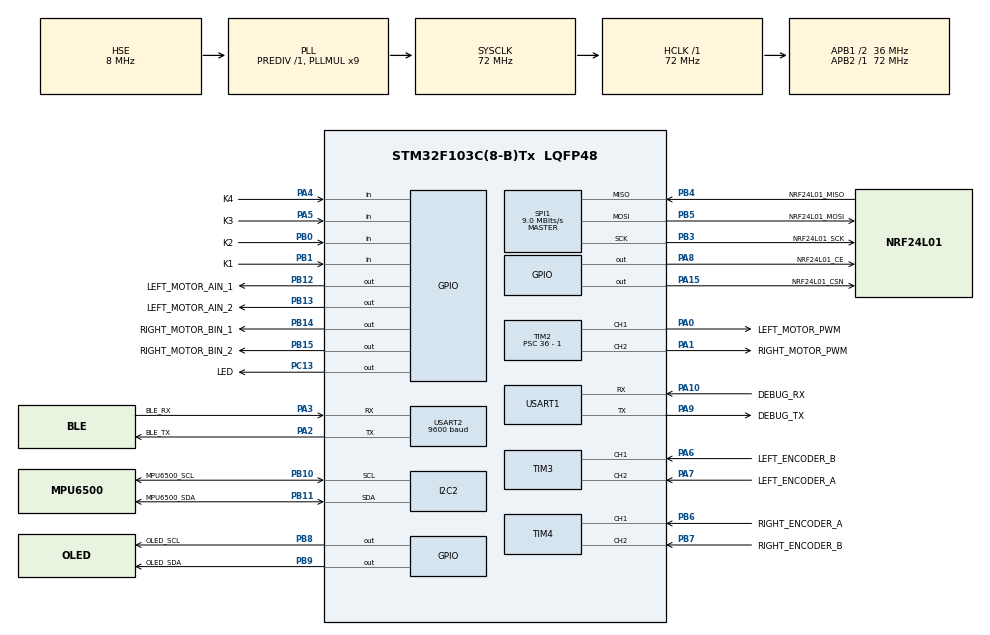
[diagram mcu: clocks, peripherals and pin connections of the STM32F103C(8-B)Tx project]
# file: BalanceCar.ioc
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FREERTOS.Tasks01=defaultTask,24,128,StartDefaultTask,Default,NULL,Dynamic,NULL,NULL
FREERTOS.configTOTAL_HEAP_SIZE=6144
Mcu.Family=STM32F1
Mcu.Name=STM32F103C(8-B)Tx
Mcu.Package=LQFP48
NVIC.PriorityGroup=NVIC_PRIORITYGROUP_4
NVIC.TIM1_UP_IRQn=true\:15\:0\:false\:false\:true\:false\:false\:true\:true
NVIC.TimeBase=TIM1_UP_IRQn
NVIC.TimeBaseIP=TIM1
NVIC.USART1_IRQn=true\:10\:0\:true\:false\:true\:true\:true\:true\:true
NVIC.USART2_IRQn=true\:7\:0\:true\:false\:true\:true\:true\:true\:true
PA0-WKUP.GPIO_Label=LEFT_MOTOR_PWM
PA0-WKUP.Signal=S_TIM2_CH1_ETR
PA1.GPIO_Label=RIGHT_MOTOR_PWM
PA1.Signal=S_TIM2_CH2
PA10.GPIO_Label=DEBUG_RX
PA10.Mode=Asynchronous
PA10.Signal=USART1_RX
PA13.Mode=Serial_Wire
PA13.Signal=SYS_JTMS-SWDIO
PA14.Mode=Serial_Wire
PA14.Signal=SYS_JTCK-SWCLK
PA15.GPIO_Label=NRF24L01_CSN
PA15.PinState=GPIO_PIN_SET
PA15.Signal=GPIO_Output
PA2.GPIO_Label=BLE_TX
PA2.Mode=Asynchronous
PA2.Signal=USART2_TX
PA3.GPIO_Label=BLE_RX
PA3.Mode=Asynchronous
PA3.Signal=USART2_RX
PA4.GPIO_Label=K4
PA4.GPIO_PuPd=GPIO_PULLUP
PA4.Signal=GPIO_Input
PA5.GPIO_Label=K3
PA5.GPIO_PuPd=GPIO_PULLUP
PA5.Signal=GPIO_Input
PA6.GPIO_Label=LEFT_ENCODER_B
PA6.Signal=S_TIM3_CH1
PA7.GPIO_Label=LEFT_ENCODER_A
PA7.Signal=S_TIM3_CH2
PA8.GPIO_Label=NRF24L01_CE
PA8.Signal=GPIO_Output
PA9.GPIO_Label=DEBUG_TX
PA9.Mode=Asynchronous
PA9.Signal=USART1_TX
PB0.GPIO_Label=K2
PB0.GPIO_PuPd=GPIO_PULLUP
PB0.Signal=GPIO_Input
PB1.GPIO_Label=K1
PB1.GPIO_PuPd=GPIO_PULLUP
PB1.Signal=GPIO_Input
PB10.GPIO_Label=MPU6500_SCL
PB10.Mode=I2C
PB10.Signal=I2C2_SCL
PB11.GPIO_Label=MPU6500_SDA
PB11.Mode=I2C
PB11.Signal=I2C2_SDA
PB12.GPIO_Label=LEFT_MOTOR_AIN_1
PB12.Signal=GPIO_Output
PB13.GPIO_Label=LEFT_MOTOR_AIN_2
PB13.Signal=GPIO_Output
PB14.GPIO_Label=RIGHT_MOTOR_BIN_1
PB14.Signal=GPIO_Output
PB15.GPIO_Label=RIGHT_MOTOR_BIN_2
PB15.Signal=GPIO_Output
PB3.GPIO_Label=NRF24L01_SCK
PB3.Mode=Full_Duplex_Master
PB3.Signal=SPI1_SCK
PB4.GPIO_Label=NRF24L01_MISO
PB4.GPIO_PuPd=GPIO_PULLUP
PB4.Mode=Full_Duplex_Master
PB4.Signal=SPI1_MISO
PB5.GPIO_Label=NRF24L01_MOSI
PB5.Mode=Full_Duplex_Master
PB5.Signal=SPI1_MOSI
PB6.GPIO_Label=RIGHT_ENCODER_A
PB6.Signal=S_TIM4_CH1
PB7.GPIO_Label=RIGHT_ENCODER_B
PB7.Signal=S_TIM4_CH2
PB8.GPIO_Label=OLED_SCL
PB8.GPIO_ModeDefaultOutputPP=GPIO_MODE_OUTPUT_OD
PB8.GPIO_PuPd=GPIO_NOPULL
PB8.PinState=GPIO_PIN_SET
PB8.Signal=GPIO_Output
PB9.GPIO_Label=OLED_SDA
PB9.GPIO_ModeDefaultOutputPP=GPIO_MODE_OUTPUT_OD
PB9.GPIO_PuPd=GPIO_NOPULL
PB9.PinState=GPIO_PIN_SET
PB9.Signal=GPIO_Output
PC13-TAMPER-RTC.GPIO_Label=LED
PC13-TAMPER-RTC.PinState=GPIO_PIN_SET
PC13-TAMPER-RTC.Signal=GPIO_Output
PC14-OSC32_IN.Mode=LSE-External-Oscillator
PC14-OSC32_IN.Signal=RCC_OSC32_IN
PC15-OSC32_OUT.Mode=LSE-External-Oscillator
PC15-OSC32_OUT.Signal=RCC_OSC32_OUT
PD0-OSC_IN.Mode=HSE-External-Oscillator
PD0-OSC_IN.Signal=RCC_OSC_IN
PD1-OSC_OUT.Mode=HSE-External-Oscillator
PD1-OSC_OUT.Signal=RCC_OSC_OUT
ProjectManager.HeapSize=0x200
ProjectManager.StackSize=0x400
ProjectManager.TargetToolchain=MDK-ARM V5.32
RCC.AHBFreq_Value=72000000
RCC.APB1CLKDivider=RCC_HCLK_DIV2
RCC.APB1Freq_Value=36000000
RCC.APB1TimFreq_Value=72000000
RCC.APB2Freq_Value=72000000
RCC.APB2TimFreq_Value=72000000
RCC.HCLKFreq_Value=72000000
RCC.PLLMUL=RCC_PLL_MUL9
RCC.PLLSourceVirtual=RCC_PLLSOURCE_HSE
RCC.SYSCLKFreq_VALUE=72000000
RCC.SYSCLKSource=RCC_SYSCLKSOURCE_PLLCLK
RCC.USBFreq_Value=72000000
SH.S_TIM2_CH1_ETR.0=TIM2_CH1,PWM Generation1 CH1
SH.S_TIM2_CH2.0=TIM2_CH2,PWM Generation2 CH2
SH.S_TIM3_CH1.0=TIM3_CH1,Encoder_Interface
SH.S_TIM3_CH2.0=TIM3_CH2,Encoder_Interface
SH.S_TIM4_CH1.0=TIM4_CH1,Encoder_Interface
SH.S_TIM4_CH2.0=TIM4_CH2,Encoder_Interface
SPI1.BaudRatePrescaler=SPI_BAUDRATEPRESCALER_8
SPI1.CalculateBaudRate=9.0 MBits/s
SPI1.Direction=SPI_DIRECTION_2LINES
SPI1.Mode=SPI_MODE_MASTER
SPI1.VirtualType=VM_MASTER
TIM2.Channel-PWM\ Generation1\ CH1=TIM_CHANNEL_1
TIM2.Channel-PWM\ Generation2\ CH2=TIM_CHANNEL_2
TIM2.Period=100 - 1
TIM2.Prescaler=36 - 1
TIM3.EncoderMode=TIM_ENCODERMODE_TI12
TIM3.IC1Filter=15
TIM3.IC2Filter=15
TIM4.EncoderMode=TIM_ENCODERMODE_TI12
TIM4.IC1Filter=15
TIM4.IC2Filter=15
USART1.VirtualMode=VM_ASYNC
USART2.BaudRate=9600
USART2.VirtualMode=VM_ASYNC
VP_FREERTOS_VS_CMSIS_V2.Mode=CMSIS_V2
VP_SYS_VS_tim1.Mode=TIM1
VP_TIM2_VS_ClockSourceINT.Mode=Internal
board=custom

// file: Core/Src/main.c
/* USER CODE BEGIN Header */
/**
  ******************************************************************************
  * @file           : main.c
  * @brief          : Main program body
  ******************************************************************************
  * @attention
  *
  * Copyright (c) 2026 STMicroelectronics.
  * All rights reserved.
  *
  * This software is licensed under terms that can be found in the LICENSE file
  * in the root directory of this software component.
  * If no LICENSE file comes with this software, it is provided AS-IS.
  *
  ******************************************************************************
  */
/* USER CODE END Header */
#include "main.h"
#include "cmsis_os.h"
#include "i2c.h"
#include "spi.h"
#include "tim.h"
#include "usart.h"
#include "gpio.h"

void SystemClock_Config(void);
void MX_FREERTOS_Init(void);

int main(void)
{

  /* MCU Configuration--------------------------------------------------------*/

  /* Reset of all peripherals, Initializes the Flash interface and the Systick. */
  HAL_Init();

  /* Configure the system clock */
  SystemClock_Config();

  /* Initialize all configured peripherals */
  MX_GPIO_Init();
  MX_USART1_UART_Init();
  MX_I2C2_Init();
  MX_SPI1_Init();
  MX_USART2_UART_Init();
  MX_TIM2_Init();
  MX_TIM3_Init();
  MX_TIM4_Init();

  /* Init scheduler */
  osKernelInitialize();  /* Call init function for freertos objects (in cmsis_os2.c) */
  MX_FREERTOS_Init();

  /* Start scheduler */
  osKernelStart();

  /* We should never get here as control is now taken by the scheduler */

  /* Infinite loop */
  while (1)
  {

  }
}

void SystemClock_Config(void)
{
  RCC_OscInitTypeDef RCC_OscInitStruct = {0};
  RCC_ClkInitTypeDef RCC_ClkInitStruct = {0};

  /** Initializes the RCC Oscillators according to the specified parameters
  * in the RCC_OscInitTypeDef structure.
  */
  RCC_OscInitStruct.OscillatorType = RCC_OSCILLATORTYPE_HSE;
  RCC_OscInitStruct.HSEState = RCC_HSE_ON;
  RCC_OscInitStruct.HSEPredivValue = RCC_HSE_PREDIV_DIV1;
  RCC_OscInitStruct.HSIState = RCC_HSI_ON;
  RCC_OscInitStruct.PLL.PLLState = RCC_PLL_ON;
  RCC_OscInitStruct.PLL.PLLSource = RCC_PLLSOURCE_HSE;
  RCC_OscInitStruct.PLL.PLLMUL = RCC_PLL_MUL9;
  if (HAL_RCC_OscConfig(&RCC_OscInitStruct) != HAL_OK)
  {
    Error_Handler();
  }

  /** Initializes the CPU, AHB and APB buses clocks
  */
  RCC_ClkInitStruct.ClockType = RCC_CLOCKTYPE_HCLK|RCC_CLOCKTYPE_SYSCLK
                              |RCC_CLOCKTYPE_PCLK1|RCC_CLOCKTYPE_PCLK2;
  RCC_ClkInitStruct.SYSCLKSource = RCC_SYSCLKSOURCE_PLLCLK;
  RCC_ClkInitStruct.AHBCLKDivider = RCC_SYSCLK_DIV1;
  RCC_ClkInitStruct.APB1CLKDivider = RCC_HCLK_DIV2;
  RCC_ClkInitStruct.APB2CLKDivider = RCC_HCLK_DIV1;

  if (HAL_RCC_ClockConfig(&RCC_ClkInitStruct, FLASH_LATENCY_2) != HAL_OK)
  {
    Error_Handler();
  }
}

void HAL_TIM_PeriodElapsedCallback(TIM_HandleTypeDef *htim)
{
  if (htim->Instance == TIM1)
  {
    HAL_IncTick();
  }
}

void Error_Handler(void)
{
  __disable_irq();
  while (1)
  {
  }
}

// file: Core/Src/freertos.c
/* USER CODE BEGIN Header */
/**
 ******************************************************************************
 * File Name          : freertos.c
 * Description        : Code for freertos applications
 ******************************************************************************
 * @attention
 *
 * Copyright (c) 2026 STMicroelectronics.
 * All rights reserved.
 *
 * This software is licensed under terms that can be found in the LICENSE file
 * in the root directory of this software component.
 * If no LICENSE file comes with this software, it is provided AS-IS.
 *
 ******************************************************************************
 */
/* USER CODE END Header */

#include "FreeRTOS.h"
#include "task.h"
#include "main.h"
#include "cmsis_os.h"

/* USER CODE BEGIN Includes */
#include "app_task.h"
/* USER CODE END Includes */

/* Definitions for defaultTask */
osThreadId_t defaultTaskHandle;
const osThreadAttr_t defaultTask_attributes = {
  .name = "defaultTask",
  .stack_size = 128 * 4,
  .priority = (osPriority_t) osPriorityNormal,
};

void StartDefaultTask(void *argument);

void MX_FREERTOS_Init(void); /* (MISRA C 2004 rule 8.1) */

void MX_FREERTOS_Init(void) {
  /* USER CODE BEGIN Init */
  // 创建应用任务
  App_Task_Create();
  /* USER CODE END Init */

  /* Create the thread(s) */
  /* creation of defaultTask */
  defaultTaskHandle = osThreadNew(StartDefaultTask, NULL, &defaultTask_attributes);

}

void StartDefaultTask(void *argument)
{
  for (;;)
  {
    osDelay(1);
  }
}
